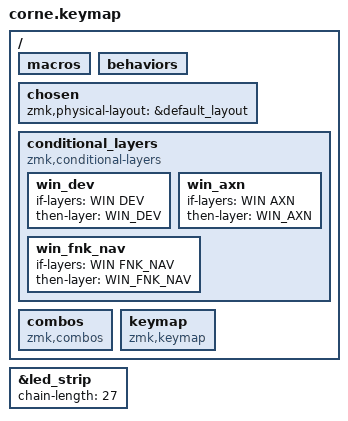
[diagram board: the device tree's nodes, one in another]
/*
 * Copyright (c) 2020 The ZMK Contributors
 *
 * SPDX-License-Identifier: MIT
 */

#include <behaviors.dtsi>
#include <dt-bindings/zmk/keys.h>
#include <dt-bindings/zmk/bt.h>
#include <dt-bindings/zmk/rgb.h>

/* ZMK Studio */
#include "layout/corne.dtsi"

/* Hardware: nice!view CS pin override -- see the file, this is load-bearing */
#include "layout/nice_view.dtsi"

/* Global */
#include "os/shared/times.dtsi"
#include "os/shared/general.dtsi"
#include "os/shared/layers.dtsi"

/* Helpers -- must precede anything that instantiates them */
#include "helpers/macros.dtsi"
#include "helpers/morph.dtsi"

/* Keys */
#include "os/shared/keys.dtsi"

/ {
    macros {
        #include "os/shared/macros/layers.dtsi"
    };
};

/ {
    behaviors {
        #include "os/shared/hold/shared.dtsi"
        #include "os/shared/morph/shared.dtsi"
        #include "os/shared/morph/rgb.dtsi"
        #include "os/shared/morph/actions.dtsi"
        #include "os/windows/morph/actions.dtsi"

    };
};

/* Bluetooth macros sit after the behaviors block because they reference
 * mod-morphs (mp_sSTG_cb) and the to_BAS / to_BAS_win macros. */
/ {
    macros {
        #include "os/shared/macros/settings.dtsi"
    };
};

/ {
    chosen {
        zmk,physical-layout = &default_layout;
    };
};

/* Windows overlays come up automatically whenever the WIN flag is lit and
 * the matching typing layer is active. This is what lets the firmware emit
 * native Windows keycodes instead of depending on a host-side remap. */
/ {
    conditional_layers {
        compatible = "zmk,conditional-layers";

        win_dev {
            if-layers = <WIN DEV>;
            then-layer = <WIN_DEV>;
        };

        win_axn {
            if-layers = <WIN AXN>;
            then-layer = <WIN_AXN>;
        };

        win_fnk_nav {
            if-layers = <WIN FNK_NAV>;
            then-layer = <WIN_FNK_NAV>;
        };
    };
};

/* 21 per-key + 6 underglow per half. Upstream defaults to an
 * arbitrary 10, which would leave LEDs 11-27 dark. */
&led_strip {
    chain-length = <27>;
};

/ {
    combos {
        compatible = "zmk,combos";

        #include "os/shared/combos.dtsi"
    };
};

/* LAYER ORDER. ZMK assigns indices by node order, so this include list is
 * what actually decides them -- os/shared/layers.dtsi only names them, and
 * check-keymap.sh asserts the two agree.
 *
 * WIN is deliberately second, directly above BAS and below the typing
 * layers, so the OLED reports the layer in use rather than permanently
 * reading "WIN" in Windows mode. That only works while the typing layers
 * stay &trans at positions 0, 11 and 12. See os/shared/layers.dtsi. */
/ {
    keymap {
        compatible = "zmk,keymap";

        #include "os/shared/keymap/base.dtsi"        /* 0  BAS     */
        #include "os/windows/keymap/flag.dtsi"       /* 1  WIN     */
        #include "os/shared/keymap/typing.dtsi"      /* 2  DEV     */
                                                    /* 3  AXN     */
                                                    /* 4  FNK_NAV */
                                                    /* 5  STG     */
        #include "os/windows/keymap/dev.dtsi"        /* 6  WIN_DEV     */
        #include "os/windows/keymap/act_num.dtsi"    /* 7  WIN_AXN     */
        #include "os/windows/keymap/fnk_nav.dtsi"    /* 8  WIN_FNK_NAV */
    };
};
